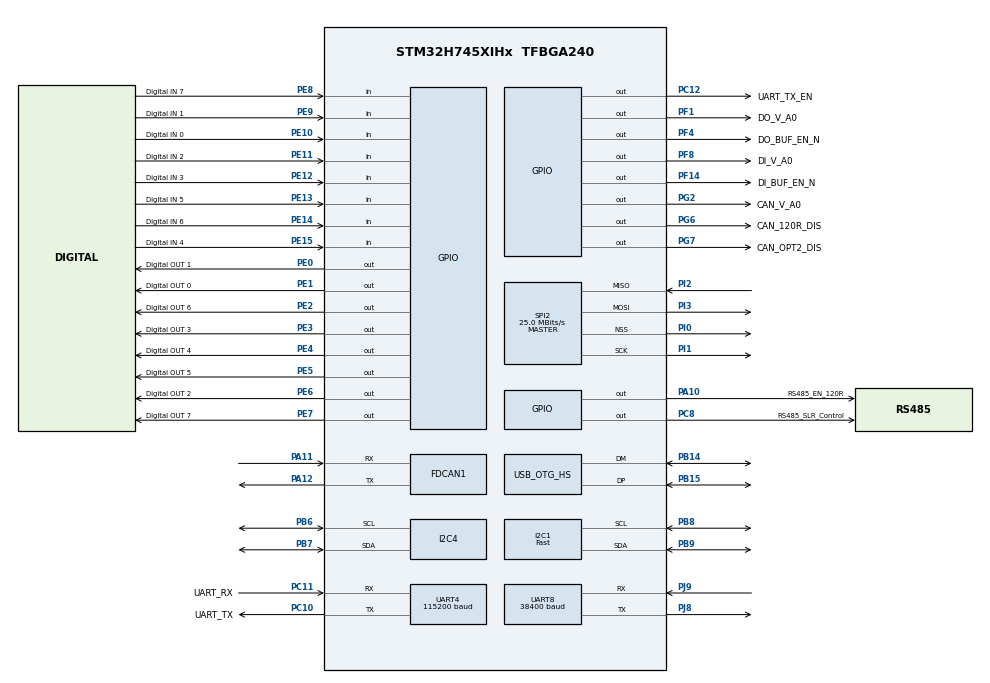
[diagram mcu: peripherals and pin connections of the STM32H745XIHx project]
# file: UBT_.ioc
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CortexM4.IPs=BDMA,CORTEX_M4\:I,DEBUG,DMA,FATFS_M4\:I,FREERTOS_M4\:I,GPIO,IWDG2\:I,MDMA,NVIC2\:I,OPENAMP_M4\:I,PDM2PCM_M4\:I,PWR,RCC,RESMGR_UTILITY,SYS_M4\:I,USB_DEVICE_M4\:I,USB_HOST_M4\:I,VREFBUF,WWDG2\:I
CortexM7.IPs=BDMA\:I,CORTEX_M7\:I,DEBUG\:I,DMA\:I,FATFS_M7\:I,FREERTOS_M7\:I,GPIO\:I,IWDG1\:I,MDMA\:I,NVIC1\:I,OPENAMP_M7\:I,PDM2PCM_M7\:I,PWR\:I,RCC\:I,RESMGR_UTILITY\:I,SYS\:I,USB_DEVICE_M7\:I,USB_HOST_M7\:I,VREFBUF\:I,WWDG1\:I,USB_OTG_HS\:I,UART8\:I,I2C4\:I,I2C1\:I,SPI2\:I,UART4\:I,FDCAN1\:I
CortexM7.Pins=PE1,PE2,PE0,PC12,PE5,PE4,PE3,PA10,PE6,PC8,PG7,PF1,PG6,PG2,PF4,PF8,PE10,PF14,PE9,PE11,PE12,PE15,PE8,PE13,PE7,PE14
FDCAN1.CalculateBaudRateNominal=1250000
FDCAN1.CalculateTimeBitNominal=800
FDCAN1.CalculateTimeQuantumNominal=160.0
FDCAN1.NominalPrescaler=8
I2C1.I2C_Speed_Mode=I2C_Fast
I2C1.Speed=100
I2C1.Timing=0x20000215
I2C4.Timing=0x00303D5B
Mcu.Family=STM32H7
Mcu.Name=STM32H745XIHx
Mcu.Package=TFBGA240
NVIC1.OTG_HS_EP1_IN_IRQn=true\:0\:0\:false\:false\:true\:true\:true\:true
NVIC1.OTG_HS_IRQn=true\:0\:0\:false\:false\:true\:false\:true\:true
NVIC1.PriorityGroup=NVIC_PRIORITYGROUP_4
NVIC2.PriorityGroup=NVIC_PRIORITYGROUP_4
PA10.GPIO_Label=RS485_EN_120R
PA10.PinAttribute=CortexM7
PA10.Signal=GPIO_Output
PA11.Mode=FDCAN_Activate
PA11.PinAttribute=CortexM7
PA11.Signal=FDCAN1_RX
PA12.Mode=FDCAN_Activate
PA12.PinAttribute=CortexM7
PA12.Signal=FDCAN1_TX
PB14.Mode=Device_Only_FS
PB14.PinAttribute=CortexM7
PB14.Signal=USB_OTG_HS_DM
PB15.Mode=Device_Only_FS
PB15.PinAttribute=CortexM7
PB15.Signal=USB_OTG_HS_DP
PB6.Mode=I2C
PB6.PinAttribute=CortexM7
PB6.Signal=I2C4_SCL
PB7.Mode=I2C
PB7.PinAttribute=CortexM7
PB7.Signal=I2C4_SDA
PB8.GPIO_Pu=GPIO_NOPULL
PB8.GPIO_Speed=GPIO_SPEED_FREQ_LOW
PB8.Mode=I2C
PB8.PinAttribute=CortexM7
PB8.Signal=I2C1_SCL
PB9.GPIO_Pu=GPIO_NOPULL
PB9.GPIO_Speed=GPIO_SPEED_FREQ_LOW
PB9.Mode=I2C
PB9.PinAttribute=CortexM7
PB9.Signal=I2C1_SDA
PC10.GPIO_Label=UART_TX
PC10.Mode=Asynchronous
PC10.PinAttribute=CortexM7
PC10.Signal=UART4_TX
PC11.GPIO_Label=UART_RX
PC11.Mode=Asynchronous
PC11.PinAttribute=CortexM7
PC11.Signal=UART4_RX
PC12.GPIO_Label=UART_TX_EN
PC12.PinAttribute=CortexM7
PC12.Signal=GPIO_Output
PC8.GPIO_Label=RS485_SLR_Control
PC8.PinAttribute=CortexM7
PC8.Signal=GPIO_Output
PE0.GPIO_Label=Digital OUT 1
PE0.GPIO_ModeDefaultOutputPP=GPIO_MODE_OUTPUT_PP
PE0.GPIO_PuPd=GPIO_PULLUP
PE0.GPIO_Speed=GPIO_SPEED_FREQ_LOW
PE0.PinAttribute=CortexM7
PE0.PinState=GPIO_PIN_RESET
PE0.Signal=GPIO_Output
PE1.GPIO_Label=Digital OUT 0
PE1.GPIO_ModeDefaultOutputPP=GPIO_MODE_OUTPUT_PP
PE1.GPIO_PuPd=GPIO_PULLUP
PE1.GPIO_Speed=GPIO_SPEED_FREQ_LOW
PE1.PinAttribute=CortexM7
PE1.PinState=GPIO_PIN_RESET
PE1.Signal=GPIO_Output
PE10.GPIO_Label=Digital IN 0
PE10.GPIO_Mode=GPIO_MODE_INPUT
PE10.GPIO_PuPd=GPIO_PULLUP
PE10.PinAttribute=CortexM7
PE10.Signal=GPIO_Input
PE11.GPIO_Label=Digital IN 2
PE11.GPIO_Mode=GPIO_MODE_INPUT
PE11.GPIO_PuPd=GPIO_PULLUP
PE11.PinAttribute=CortexM7
PE11.Signal=GPIO_Input
PE12.GPIO_Label=Digital IN 3
PE12.GPIO_Mode=GPIO_MODE_INPUT
PE12.GPIO_PuPd=GPIO_PULLUP
PE12.PinAttribute=CortexM7
PE12.Signal=GPIO_Input
PE13.GPIO_Label=Digital IN 5
PE13.GPIO_Mode=GPIO_MODE_INPUT
PE13.GPIO_PuPd=GPIO_PULLUP
PE13.PinAttribute=CortexM7
PE13.Signal=GPIO_Input
PE14.GPIO_Label=Digital IN 6
PE14.GPIO_Mode=GPIO_MODE_INPUT
PE14.GPIO_PuPd=GPIO_PULLUP
PE14.PinAttribute=CortexM7
PE14.Signal=GPIO_Input
PE15.GPIO_Label=Digital IN 4
PE15.GPIO_Mode=GPIO_MODE_INPUT
PE15.GPIO_PuPd=GPIO_PULLUP
PE15.PinAttribute=CortexM7
PE15.Signal=GPIO_Input
PE2.GPIO_Label=Digital OUT 6
PE2.GPIO_ModeDefaultOutputPP=GPIO_MODE_OUTPUT_PP
PE2.GPIO_PuPd=GPIO_PULLUP
PE2.GPIO_Speed=GPIO_SPEED_FREQ_LOW
PE2.PinAttribute=CortexM7
PE2.PinState=GPIO_PIN_RESET
PE2.Signal=GPIO_Output
PE3.GPIO_Label=Digital OUT 3
PE3.GPIO_ModeDefaultOutputPP=GPIO_MODE_OUTPUT_PP
PE3.GPIO_PuPd=GPIO_PULLUP
PE3.GPIO_Speed=GPIO_SPEED_FREQ_LOW
PE3.PinAttribute=CortexM7
PE3.PinState=GPIO_PIN_RESET
PE3.Signal=GPIO_Output
PE4.GPIO_Label=Digital OUT 4
PE4.GPIO_ModeDefaultOutputPP=GPIO_MODE_OUTPUT_PP
PE4.GPIO_PuPd=GPIO_PULLUP
PE4.GPIO_Speed=GPIO_SPEED_FREQ_LOW
PE4.PinAttribute=CortexM7
PE4.PinState=GPIO_PIN_RESET
PE4.Signal=GPIO_Output
PE5.GPIO_Label=Digital OUT 5
PE5.GPIO_ModeDefaultOutputPP=GPIO_MODE_OUTPUT_PP
PE5.GPIO_PuPd=GPIO_PULLUP
PE5.GPIO_Speed=GPIO_SPEED_FREQ_LOW
PE5.PinAttribute=CortexM7
PE5.PinState=GPIO_PIN_RESET
PE5.Signal=GPIO_Output
PE6.GPIO_Label=Digital OUT 2
PE6.GPIO_ModeDefaultOutputPP=GPIO_MODE_OUTPUT_PP
PE6.GPIO_PuPd=GPIO_PULLUP
PE6.GPIO_Speed=GPIO_SPEED_FREQ_LOW
PE6.PinAttribute=CortexM7
PE6.PinState=GPIO_PIN_RESET
PE6.Signal=GPIO_Output
PE7.GPIO_Label=Digital OUT 7
PE7.GPIO_ModeDefaultOutputPP=GPIO_MODE_OUTPUT_PP
PE7.GPIO_PuPd=GPIO_PULLUP
PE7.GPIO_Speed=GPIO_SPEED_FREQ_LOW
PE7.PinAttribute=CortexM7
PE7.PinState=GPIO_PIN_RESET
PE7.Signal=GPIO_Output
PE8.GPIO_Label=Digital IN 7
PE8.GPIO_Mode=GPIO_MODE_INPUT
PE8.GPIO_PuPd=GPIO_PULLUP
PE8.PinAttribute=CortexM7
PE8.Signal=GPIO_Input
PE9.GPIO_Label=Digital IN 1
PE9.GPIO_Mode=GPIO_MODE_INPUT
PE9.GPIO_PuPd=GPIO_PULLUP
PE9.PinAttribute=CortexM7
PE9.Signal=GPIO_Input
PF1.GPIO_Label=DO_V_A0
PF1.PinAttribute=CortexM7
PF1.Signal=GPIO_Output
PF14.GPIO_Label=DI_BUF_EN_N
PF14.PinAttribute=CortexM7
PF14.Signal=GPIO_Output
PF4.GPIO_Label=DO_BUF_EN_N
PF4.PinAttribute=CortexM7
PF4.Signal=GPIO_Output
PF8.GPIO_Label=DI_V_A0
PF8.PinAttribute=CortexM7
PF8.Signal=GPIO_Output
PG2.GPIO_Label=CAN_V_A0
PG2.PinAttribute=CortexM7
PG2.Signal=GPIO_Output
PG6.GPIO_Label=CAN_120R_DIS
PG6.GPIO_PuPd=GPIO_PULLDOWN
PG6.PinAttribute=CortexM7
PG6.Signal=GPIO_Output
PG7.GPIO_Label=CAN_OPT2_DIS
PG7.GPIO_PuPd=GPIO_PULLDOWN
PG7.PinAttribute=CortexM7
PG7.Signal=GPIO_Output
PI0.Mode=NSS_Signal_Hard_Output
PI0.PinAttribute=CortexM7
PI0.Signal=SPI2_NSS
PI1.Mode=Full_Duplex_Master
PI1.PinAttribute=CortexM7
PI1.Signal=SPI2_SCK
PI2.Mode=Full_Duplex_Master
PI2.PinAttribute=CortexM7
PI2.Signal=SPI2_MISO
PI3.Mode=Full_Duplex_Master
PI3.PinAttribute=CortexM7
PI3.Signal=SPI2_MOSI
PJ8.Mode=Asynchronous
PJ8.PinAttribute=CortexM7
PJ8.Signal=UART8_TX
PJ9.Mode=Asynchronous
PJ9.PinAttribute=CortexM7
PJ9.Signal=UART8_RX
ProjectManager.HeapSize=M4-0x200,M7-0x200
ProjectManager.StackSize=M4-0x400,M7-0x400
ProjectManager.TargetToolchain=STM32CubeIDE
RCC.ADCFreq_Value=8062500
RCC.APB1Freq_Value=8000000
RCC.APB2Freq_Value=16000000
RCC.APB3Freq_Value=16000000
RCC.APB4Freq_Value=16000000
RCC.CortexFreq_Value=32000000
RCC.D1PPRE=RCC_APB3_DIV2
RCC.D2PPRE1=RCC_APB1_DIV4
RCC.D2PPRE2=RCC_APB2_DIV2
RCC.D3PPRE=RCC_APB4_DIV2
RCC.DIVM1=1
RCC.DIVM3=1
RCC.DIVN1=37
RCC.DIVN3=37
RCC.DIVQ1=3
RCC.DIVQ3=3
RCC.HCLKFreq_Value=32000000
RCC.HSIDiv=RCC_PLLSAIDIVR_2
RCC.PLL3FRACN=4096
RCC.PLLFRACN=4096
RCC.PLLSourceVirtual=RCC_PLLSOURCE_CSI
RCC.SYSCLKFreq_VALUE=32000000
RCC.SupplySource=PWR_LDO_SUPPLY
RCC.USART234578CLockSelection=RCC_USART234578CLKSOURCE_PLL3
RCC.USBCLockSelection=RCC_USBCLKSOURCE_HSI48
RCC.USBFreq_Value=48000000
SPI2.CalculateBaudRate=25.0 MBits/s
SPI2.Direction=SPI_DIRECTION_2LINES
SPI2.Mode=SPI_MODE_MASTER
SPI2.VirtualNSS=VM_NSSHARD
SPI2.VirtualType=VM_MASTER
SYS.userName=SYS_M7
UART4.BaudRate=115200
UART8.BaudRate=38400
USB_DEVICE_M7.CLASS_NAME_HS=CDC
USB_DEVICE_M7.PRODUCT_STRING_CDC_HS=Universal Bridge V1.0
USB_DEVICE_M7.VirtualMode-CDC_HS=Cdc
USB_DEVICE_M7.VirtualModeHS=Cdc_HS
USB_OTG_HS.VirtualMode-Device_Only_FS=Device_Only_FS
VP_PWR_V_PVD_IN.Mode=Mode_PVD_Int
VP_SYS_M4_VS_Systick.Mode=SysTick
VP_USB_DEVICE_M7_VS_USB_DEVICE_CDC_HS.Mode=CDC_HS
board=custom

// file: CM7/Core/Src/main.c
/* USER CODE BEGIN Header */
/**
  ******************************************************************************
  * @file           : main.c
  * @brief          : Main program body
  ******************************************************************************
  * @attention
  *
  * Copyright (c) 2025 STMicroelectronics.
  * All rights reserved.
  *
  * This software is licensed under terms that can be found in the LICENSE file
  * in the root directory of this software component.
  * If no LICENSE file comes with this software, it is provided AS-IS.
  *
  ******************************************************************************
  */
/* USER CODE END Header */
#include "main.h"
#include "fdcan.h"
#include "i2c.h"
#include "spi.h"
#include "usart.h"
#include "usb_device.h"
#include "gpio.h"

/* USER CODE BEGIN Includes */
#include "cli.h"
/* USER CODE END Includes */

/* USER CODE BEGIN PD */

#ifndef HSEM_ID_0
#define HSEM_ID_0 (0U) /* HW semaphore 0*/
#endif

/* USER CODE END PD */

void SystemClock_Config(void);
void PeriphCommonClock_Config(void);

int main(void)
{
/* USER CODE BEGIN Boot_Mode_Sequence_0 */
  int32_t timeout;
/* USER CODE END Boot_Mode_Sequence_0 */

/* USER CODE BEGIN Boot_Mode_Sequence_1 */
  /* Wait until CPU2 boots and enters in stop mode or timeout*/
  timeout = 0xFFFF;
  while((__HAL_RCC_GET_FLAG(RCC_FLAG_D2CKRDY) != RESET) && (timeout-- > 0));
  if ( timeout < 0 )
  {
  Error_Handler();
  }
/* USER CODE END Boot_Mode_Sequence_1 */
  /* MCU Configuration--------------------------------------------------------*/

  /* Reset of all peripherals, Initializes the Flash interface and the Systick. */
  HAL_Init();

  /* Configure the system clock */
  SystemClock_Config();

/* Configure the peripherals common clocks */
  PeriphCommonClock_Config();
/* USER CODE BEGIN Boot_Mode_Sequence_2 */
/* When system initialization is finished, Cortex-M7 will release Cortex-M4 by means of
HSEM notification */
/*HW semaphore Clock enable*/
__HAL_RCC_HSEM_CLK_ENABLE();
/*Take HSEM */
HAL_HSEM_FastTake(HSEM_ID_0);
/*Release HSEM in order to notify the CPU2(CM4)*/
HAL_HSEM_Release(HSEM_ID_0,0);
/* wait until CPU2 wakes up from stop mode */
timeout = 0xFFFF;
while((__HAL_RCC_GET_FLAG(RCC_FLAG_D2CKRDY) == RESET) && (timeout-- > 0));
if ( timeout < 0 )
{
Error_Handler();
}
/* USER CODE END Boot_Mode_Sequence_2 */

  /* Initialize all configured peripherals */
  MX_GPIO_Init();
  MX_USB_DEVICE_Init();
  MX_UART8_Init();
  MX_I2C4_Init();
  MX_I2C1_Init();
  MX_SPI2_Init();
  MX_UART4_Init();
  MX_FDCAN1_Init();
  /* USER CODE BEGIN 2 */
  //uint8_t msg[] = "Hello World from UART8!\r\n";

   //
     //PMIC_Init(&hi2c4);

       // nachdem USB connected ist / oder später per CLI:
    // PMIC_Ping();

     /*while (1)
     {

    	 //HAL_UART_Transmit(&huart8, msg, sizeof(msg)-1, HAL_MAX_DELAY);
         //HAL_Delay(1000);
     }*/
  /* USER CODE END 2 */

  /* Infinite loop */
  while (1)
  {

    /* USER CODE BEGIN 3 */
	  CLI_Process();
  }
  /* USER CODE END 3 */
}

void SystemClock_Config(void)
{
  RCC_OscInitTypeDef RCC_OscInitStruct = {0};
  RCC_ClkInitTypeDef RCC_ClkInitStruct = {0};

  /** Supply configuration update enable
  */
  HAL_PWREx_ConfigSupply(PWR_LDO_SUPPLY);

  /** Configure the main internal regulator output voltage
  */
  __HAL_PWR_VOLTAGESCALING_CONFIG(PWR_REGULATOR_VOLTAGE_SCALE3);

  while(!__HAL_PWR_GET_FLAG(PWR_FLAG_VOSRDY)) {}

  /** Initializes the RCC Oscillators according to the specified parameters
  * in the RCC_OscInitTypeDef structure.
  */
  RCC_OscInitStruct.OscillatorType = RCC_OSCILLATORTYPE_HSI48|RCC_OSCILLATORTYPE_CSI
                              |RCC_OSCILLATORTYPE_HSI;
  RCC_OscInitStruct.HSIState = RCC_HSI_DIV2;
  RCC_OscInitStruct.HSICalibrationValue = RCC_HSICALIBRATION_DEFAULT;
  RCC_OscInitStruct.HSI48State = RCC_HSI48_ON;
  RCC_OscInitStruct.CSIState = RCC_CSI_ON;
  RCC_OscInitStruct.CSICalibrationValue = RCC_CSICALIBRATION_DEFAULT;
  RCC_OscInitStruct.PLL.PLLState = RCC_PLL_ON;
  RCC_OscInitStruct.PLL.PLLSource = RCC_PLLSOURCE_CSI;
  RCC_OscInitStruct.PLL.PLLM = 1;
  RCC_OscInitStruct.PLL.PLLN = 37;
  RCC_OscInitStruct.PLL.PLLP = 2;
  RCC_OscInitStruct.PLL.PLLQ = 3;
  RCC_OscInitStruct.PLL.PLLR = 2;
  RCC_OscInitStruct.PLL.PLLRGE = RCC_PLL1VCIRANGE_2;
  RCC_OscInitStruct.PLL.PLLVCOSEL = RCC_PLL1VCOMEDIUM;
  RCC_OscInitStruct.PLL.PLLFRACN = 4096;
  if (HAL_RCC_OscConfig(&RCC_OscInitStruct) != HAL_OK)
  {
    Error_Handler();
  }

  /** Initializes the CPU, AHB and APB buses clocks
  */
  RCC_ClkInitStruct.ClockType = RCC_CLOCKTYPE_HCLK|RCC_CLOCKTYPE_SYSCLK
                              |RCC_CLOCKTYPE_PCLK1|RCC_CLOCKTYPE_PCLK2
                              |RCC_CLOCKTYPE_D3PCLK1|RCC_CLOCKTYPE_D1PCLK1;
  RCC_ClkInitStruct.SYSCLKSource = RCC_SYSCLKSOURCE_HSI;
  RCC_ClkInitStruct.SYSCLKDivider = RCC_SYSCLK_DIV1;
  RCC_ClkInitStruct.AHBCLKDivider = RCC_HCLK_DIV1;
  RCC_ClkInitStruct.APB3CLKDivider = RCC_APB3_DIV2;
  RCC_ClkInitStruct.APB1CLKDivider = RCC_APB1_DIV4;
  RCC_ClkInitStruct.APB2CLKDivider = RCC_APB2_DIV2;
  RCC_ClkInitStruct.APB4CLKDivider = RCC_APB4_DIV2;

  if (HAL_RCC_ClockConfig(&RCC_ClkInitStruct, FLASH_LATENCY_0) != HAL_OK)
  {
    Error_Handler();
  }
}

void PeriphCommonClock_Config(void)
{
  RCC_PeriphCLKInitTypeDef PeriphClkInitStruct = {0};

  /** Initializes the peripherals clock
  */
  PeriphClkInitStruct.PeriphClockSelection = RCC_PERIPHCLK_UART8|RCC_PERIPHCLK_UART4;
  PeriphClkInitStruct.PLL3.PLL3M = 1;
  PeriphClkInitStruct.PLL3.PLL3N = 37;
  PeriphClkInitStruct.PLL3.PLL3P = 2;
  PeriphClkInitStruct.PLL3.PLL3Q = 3;
  PeriphClkInitStruct.PLL3.PLL3R = 2;
  PeriphClkInitStruct.PLL3.PLL3RGE = RCC_PLL3VCIRANGE_2;
  PeriphClkInitStruct.PLL3.PLL3VCOSEL = RCC_PLL3VCOMEDIUM;
  PeriphClkInitStruct.PLL3.PLL3FRACN = 4096;
  PeriphClkInitStruct.Usart234578ClockSelection = RCC_USART234578CLKSOURCE_PLL3;
  if (HAL_RCCEx_PeriphCLKConfig(&PeriphClkInitStruct) != HAL_OK)
  {
    Error_Handler();
  }
}

void Error_Handler(void)
{
  __disable_irq();
  while (1)
  {
  }
}
